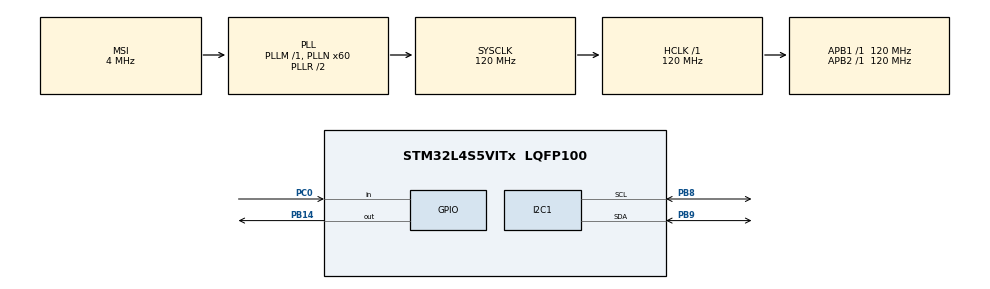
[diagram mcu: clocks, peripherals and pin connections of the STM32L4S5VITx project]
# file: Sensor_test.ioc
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I2C1.Timing=0x307075B1
Mcu.Family=STM32L4
Mcu.Name=STM32L4S5VITx
Mcu.Package=LQFP100
NVIC.PriorityGroup=NVIC_PRIORITYGROUP_4
PA13\ (JTMS/SWDIO).Signal=SYS_JTMS-SWDIO
PA14\ (JTCK/SWCLK).Signal=SYS_JTCK-SWCLK
PA2.Signal=USART2_TX
PA3.Signal=USART2_RX
PB14.Signal=GPIO_Output
PB3\ (JTDO/TRACESWO).Signal=SYS_JTDO-SWO
PB8.Mode=I2C
PB8.Signal=I2C1_SCL
PB9.Mode=I2C
PB9.Signal=I2C1_SDA
PC0.Signal=GPIO_Input
PC13.Mode=SYS_WakeUp1
PC13.Signal=SYS_WKUP2
PC14-OSC32_IN\ (PC14).Mode=LSE-External-Oscillator
PC14-OSC32_IN\ (PC14).Signal=RCC_OSC32_IN
PC15-OSC32_OUT\ (PC15).Mode=LSE-External-Oscillator
PC15-OSC32_OUT\ (PC15).Signal=RCC_OSC32_OUT
PH0-OSC_IN\ (PH0).Mode=HSE-External-Oscillator
PH0-OSC_IN\ (PH0).Signal=RCC_OSC_IN
PH1-OSC_OUT\ (PH1).Mode=HSE-External-Oscillator
PH1-OSC_OUT\ (PH1).Signal=RCC_OSC_OUT
ProjectManager.HeapSize=0x200
ProjectManager.StackSize=0x400
ProjectManager.TargetToolchain=STM32CubeIDE
RCC.ADCFreq_Value=48000000
RCC.AHBFreq_Value=120000000
RCC.APB1Freq_Value=120000000
RCC.APB1TimFreq_Value=120000000
RCC.APB2Freq_Value=120000000
RCC.APB2TimFreq_Value=120000000
RCC.CortexFreq_Value=120000000
RCC.HCLKFreq_Value=120000000
RCC.HSE_VALUE=8000000
RCC.HSI48_VALUE=48000000
RCC.HSI_VALUE=16000000
RCC.MSI_VALUE=4000000
RCC.PLLN=60
RCC.PLLSAI1N=24
RCC.SYSCLKFreq_VALUE=120000000
RCC.SYSCLKSource=RCC_SYSCLKSOURCE_PLLCLK
RCC.USBFreq_Value=48000000
RCC.VCOOutputFreq_Value=240000000
board=B-L4S5I-IOT01A

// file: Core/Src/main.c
/* USER CODE BEGIN Header */
/**
  ******************************************************************************
  * @file           : main.c
  * @brief          : Main program body
  ******************************************************************************
  * @attention
  *
  * Copyright (c) 2023 STMicroelectronics.
  * All rights reserved.
  *
  * This software is licensed under terms that can be found in the LICENSE file
  * in the root directory of this software component.
  * If no LICENSE file comes with this software, it is provided AS-IS.
  *
  ******************************************************************************
  */
/* USER CODE END Header */
#include "main.h"

I2C_HandleTypeDef hi2c1;

void SystemClock_Config(void);
static void MX_GPIO_Init(void);
static void MX_I2C1_Init(void);

int main(void)
{

  /* MCU Configuration--------------------------------------------------------*/

  /* Reset of all peripherals, Initializes the Flash interface and the Systick. */
  HAL_Init();

  /* Configure the system clock */
  SystemClock_Config();

  /* Initialize all configured peripherals */
  MX_GPIO_Init();
  MX_I2C1_Init();

  /* Infinite loop */
  /* USER CODE BEGIN WHILE */
  while (1)
  {
	  HAL_I2C_Master_Receive(hi2c, DevAddress, pData, Size, Timeout);

    /* USER CODE END WHILE */

  }
}

void SystemClock_Config(void)
{
  RCC_OscInitTypeDef RCC_OscInitStruct = {0};
  RCC_ClkInitTypeDef RCC_ClkInitStruct = {0};

  /** Configure the main internal regulator output voltage
  */
  if (HAL_PWREx_ControlVoltageScaling(PWR_REGULATOR_VOLTAGE_SCALE1_BOOST) != HAL_OK)
  {
    Error_Handler();
  }

  /** Initializes the RCC Oscillators according to the specified parameters
  * in the RCC_OscInitTypeDef structure.
  */
  RCC_OscInitStruct.OscillatorType = RCC_OSCILLATORTYPE_MSI;
  RCC_OscInitStruct.MSIState = RCC_MSI_ON;
  RCC_OscInitStruct.MSICalibrationValue = 0;
  RCC_OscInitStruct.MSIClockRange = RCC_MSIRANGE_6;
  RCC_OscInitStruct.PLL.PLLState = RCC_PLL_ON;
  RCC_OscInitStruct.PLL.PLLSource = RCC_PLLSOURCE_MSI;
  RCC_OscInitStruct.PLL.PLLM = 1;
  RCC_OscInitStruct.PLL.PLLN = 60;
  RCC_OscInitStruct.PLL.PLLP = RCC_PLLP_DIV2;
  RCC_OscInitStruct.PLL.PLLQ = RCC_PLLQ_DIV2;
  RCC_OscInitStruct.PLL.PLLR = RCC_PLLR_DIV2;
  if (HAL_RCC_OscConfig(&RCC_OscInitStruct) != HAL_OK)
  {
    Error_Handler();
  }

  /** Initializes the CPU, AHB and APB buses clocks
  */
  RCC_ClkInitStruct.ClockType = RCC_CLOCKTYPE_HCLK|RCC_CLOCKTYPE_SYSCLK
                              |RCC_CLOCKTYPE_PCLK1|RCC_CLOCKTYPE_PCLK2;
  RCC_ClkInitStruct.SYSCLKSource = RCC_SYSCLKSOURCE_PLLCLK;
  RCC_ClkInitStruct.AHBCLKDivider = RCC_SYSCLK_DIV1;
  RCC_ClkInitStruct.APB1CLKDivider = RCC_HCLK_DIV1;
  RCC_ClkInitStruct.APB2CLKDivider = RCC_HCLK_DIV1;

  if (HAL_RCC_ClockConfig(&RCC_ClkInitStruct, FLASH_LATENCY_5) != HAL_OK)
  {
    Error_Handler();
  }
}

static void MX_I2C1_Init(void)
{

  hi2c1.Instance = I2C1;
  hi2c1.Init.Timing = 0x307075B1;
  hi2c1.Init.OwnAddress1 = 0;
  hi2c1.Init.AddressingMode = I2C_ADDRESSINGMODE_7BIT;
  hi2c1.Init.DualAddressMode = I2C_DUALADDRESS_DISABLE;
  hi2c1.Init.OwnAddress2 = 0;
  hi2c1.Init.OwnAddress2Masks = I2C_OA2_NOMASK;
  hi2c1.Init.GeneralCallMode = I2C_GENERALCALL_DISABLE;
  hi2c1.Init.NoStretchMode = I2C_NOSTRETCH_DISABLE;
  if (HAL_I2C_Init(&hi2c1) != HAL_OK)
  {
    Error_Handler();
  }

  /** Configure Analogue filter
  */
  if (HAL_I2CEx_ConfigAnalogFilter(&hi2c1, I2C_ANALOGFILTER_ENABLE) != HAL_OK)
  {
    Error_Handler();
  }

  /** Configure Digital filter
  */
  if (HAL_I2CEx_ConfigDigitalFilter(&hi2c1, 0) != HAL_OK)
  {
    Error_Handler();
  }

}

static void MX_GPIO_Init(void)
{
  GPIO_InitTypeDef GPIO_InitStruct = {0};

  /* GPIO Ports Clock Enable */
  __HAL_RCC_GPIOC_CLK_ENABLE();
  __HAL_RCC_GPIOH_CLK_ENABLE();
  __HAL_RCC_GPIOA_CLK_ENABLE();
  __HAL_RCC_GPIOB_CLK_ENABLE();

  /*Configure GPIO pin Output Level */
  HAL_GPIO_WritePin(GPIOB, GPIO_PIN_14, GPIO_PIN_RESET);

  /*Configure GPIO pin : PC0 */
  GPIO_InitStruct.Pin = GPIO_PIN_0;
  GPIO_InitStruct.Mode = GPIO_MODE_INPUT;
  GPIO_InitStruct.Pull = GPIO_NOPULL;
  HAL_GPIO_Init(GPIOC, &GPIO_InitStruct);

  /*Configure GPIO pins : PA2 PA3 */
  GPIO_InitStruct.Pin = GPIO_PIN_2|GPIO_PIN_3;
  GPIO_InitStruct.Mode = GPIO_MODE_AF_PP;
  GPIO_InitStruct.Pull = GPIO_NOPULL;
  GPIO_InitStruct.Speed = GPIO_SPEED_FREQ_VERY_HIGH;
  GPIO_InitStruct.Alternate = GPIO_AF7_USART2;
  HAL_GPIO_Init(GPIOA, &GPIO_InitStruct);

  /*Configure GPIO pin : PB14 */
  GPIO_InitStruct.Pin = GPIO_PIN_14;
  GPIO_InitStruct.Mode = GPIO_MODE_OUTPUT_PP;
  GPIO_InitStruct.Pull = GPIO_NOPULL;
  GPIO_InitStruct.Speed = GPIO_SPEED_FREQ_LOW;
  HAL_GPIO_Init(GPIOB, &GPIO_InitStruct);

}

void Error_Handler(void)
{
  __disable_irq();
  while (1)
  {
  }
}
